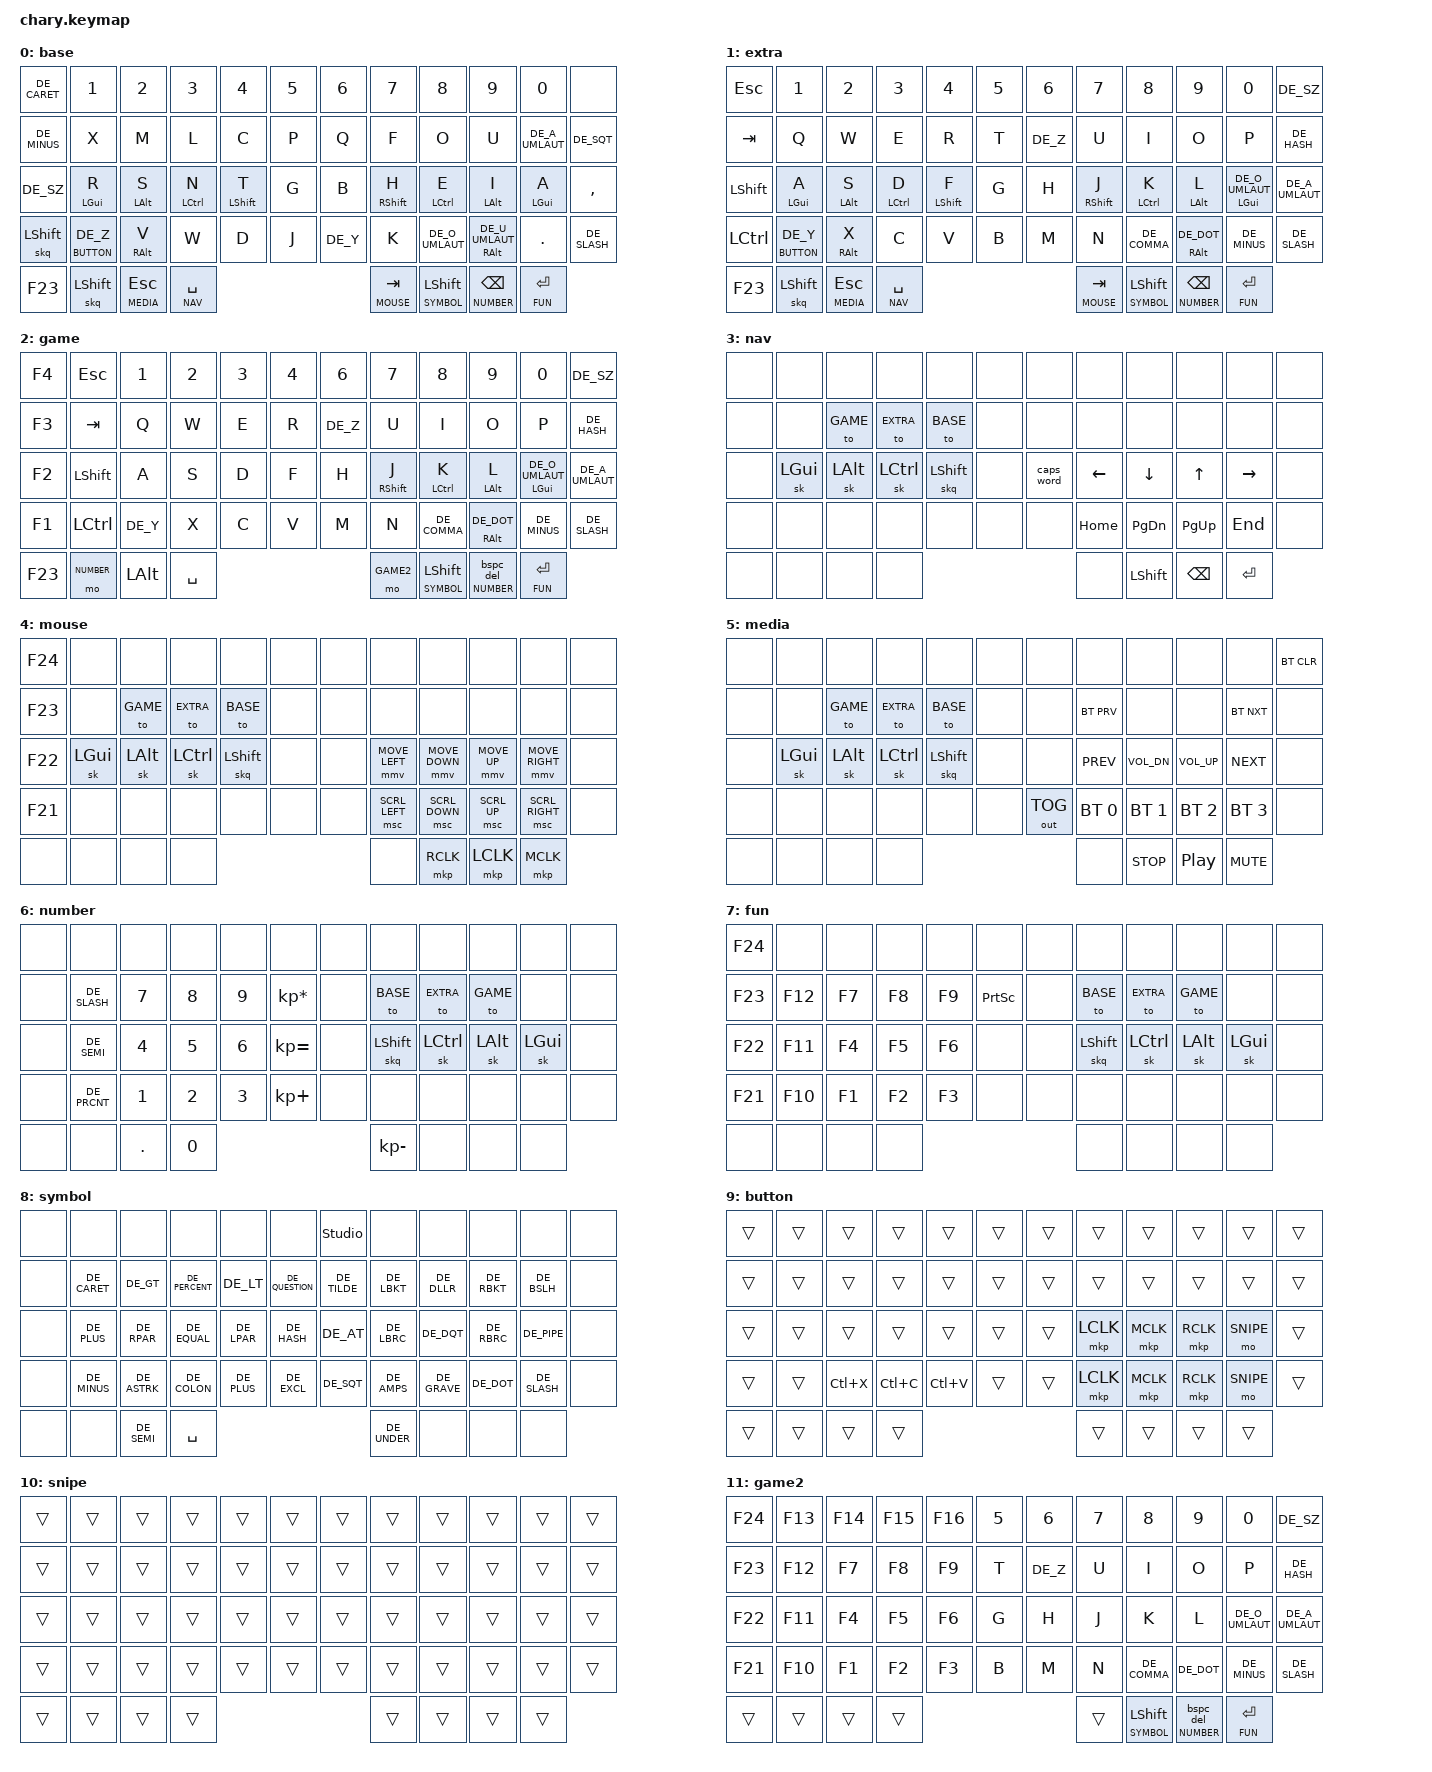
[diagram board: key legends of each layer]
#define ZMK_POINTING_DEFAULT_MOVE_VAL 1500  // default: 600
#include <behaviors.dtsi>
#include <dt-bindings/zmk/bt.h>
#include <dt-bindings/zmk/keys.h>
#include <dt-bindings/zmk/outputs.h>
#include <dt-bindings/zmk/mouse.h>
#include <locale/keys_de.h>

#define BASE    0
#define EXTRA   1
#define GAME    2
#define NAV     3
#define MOUSE   4
#define MEDIA   5
#define NUMBER  6
#define FUN     7
#define SYMBOL  8
#define BUTTON  9
#define SNIPE   10
#define GAME2   11

#define TAPPING_TERM 200
#define TAPPING_TERM_QUICK 150
#define REQUIRE_PRIOR_IDLE_MS 100

#define LEFT_THUMB 48 49 50 51 52
#define RIGHT_THUMB 53 54 55
#define LEFT_POS 0 1 2 3 4 5 12 13 14 15 16 17 24 25 26 27 28 29 36 37 38 39 40 41
#define RIGHT_POS 6 7 8 9 10 11 18 19 20 21 22 23 30 31 32 33 34 35 42 43 44 45 46 47

#include <dt-bindings/zmk/pointing.h>

&caps_word {
    continue-list = <SLASH LSHFT RSHFT>;
};

/ {
    behaviors {
        hrml: hrml {
            compatible = "zmk,behavior-hold-tap";
            #binding-cells = <2>;
            bindings = <&kp>, <&kp>;
            tapping-term-ms = <TAPPING_TERM>;
            quick-tap-ms = <175>;
            flavor = "balanced";
            hold-trigger-on-release;
            require-prior-idle-ms = <REQUIRE_PRIOR_IDLE_MS>;
            hold-trigger-key-positions = <RIGHT_POS LEFT_THUMB RIGHT_THUMB>;
        };

        hrmr: hrmr {
            compatible = "zmk,behavior-hold-tap";
            #binding-cells = <2>;
            bindings = <&kp>, <&kp>;
            tapping-term-ms = <TAPPING_TERM>;
            quick-tap-ms = <175>;
            flavor = "balanced";
            require-prior-idle-ms = <REQUIRE_PRIOR_IDLE_MS>;
            hold-trigger-key-positions = <LEFT_POS LEFT_THUMB RIGHT_THUMB>;
            hold-trigger-on-release;
        };

        hrml_s: hrml_s {
            compatible = "zmk,behavior-hold-tap";
            #binding-cells = <2>;
            bindings = <&kp>, <&kp>;
            tapping-term-ms = <TAPPING_TERM>;
            quick-tap-ms = <175>;
            flavor = "balanced";
            hold-trigger-key-positions = <RIGHT_POS LEFT_THUMB RIGHT_THUMB>;
            hold-trigger-on-release;
        };

        hrmr_s: hrmr_s {
            compatible = "zmk,behavior-hold-tap";
            #binding-cells = <2>;
            bindings = <&kp>, <&kp>;
            tapping-term-ms = <TAPPING_TERM>;
            quick-tap-ms = <175>;
            flavor = "balanced";
            hold-trigger-key-positions = <LEFT_POS LEFT_THUMB RIGHT_THUMB>;
            hold-trigger-on-release;
        };

        skq: sticky_key_quick_release {
            compatible = "zmk,behavior-sticky-key";
            #binding-cells = <1>;
            bindings = <&kp>;
            release-after-ms = <1000>;
            quick-release;
            ignore-modifiers;
        };

        bspc_del: backspace_del {
            compatible = "zmk,behavior-mod-morph";
            #binding-cells = <0>;
            bindings = <&kp BSPC>, <&kp DEL>;
            mods = <(MOD_LSFT|MOD_RSFT)>;
        };

        skq_mo: skq_mo {
            compatible = "zmk,behavior-hold-tap";
            bindings = <&mo>, <&skq>;

            #binding-cells = <2>;
            tapping-term-ms = <TAPPING_TERM_QUICK>;
            flavor = "tap-preferred";
        };

        lt_bspc: lt_bspc {
            compatible = "zmk,behavior-hold-tap";
            bindings = <&mo>, <&bspc_del>;

            #binding-cells = <2>;
            tapping-term-ms = <TAPPING_TERM_QUICK>;
            flavor = "tap-preferred";
        };
    };

    macros {
    };

    #include "combos.dtsi"

    keymap {
        compatible = "zmk,keymap";

        default_layer {
            display-name = "base";
            bindings = <
                &kp DE_CARET    &kp N1           &kp N2          &kp N3          &kp N4            &kp N5      &kp N6    &kp N7            &kp N8           &kp N9                  &kp N0           &none
                &kp DE_MINUS    &kp X            &kp M           &kp L           &kp C             &kp P       &kp Q     &kp F             &kp O            &kp U                   &kp DE_A_UMLAUT  &kp DE_SQT
                &kp DE_SZ       &hrml LGUI R     &hrml LALT S    &hrml LCTRL N   &hrml_s LSHIFT T  &kp G       &kp B     &hrmr_s RSHIFT H  &hrmr LCTRL E    &hrmr LALT I            &hrmr LGUI A     &kp COMMA
                &skq LSHFT      &lt BUTTON DE_Z  &hrml RALT V    &kp W           &kp D             &kp J       &kp DE_Y  &kp K             &kp DE_O_UMLAUT  &hrmr RALT DE_U_UMLAUT  &kp DOT          &kp DE_SLASH
                    &kp F23     &skq LSHIFT  &lt MEDIA ESC  &lt NAV SPACE  &lt MOUSE TAB                                      &skq_mo SYMBOL LSHFT  &lt NUMBER BSPC  &lt FUN ENTER
            >;
        };

        extra_layer {
            display-name = "extra";
            bindings = <
                &kp ESC   &kp N1            &kp N2        &kp N3         &kp N4             &kp N5    &kp N6   &kp N7            &kp N8          &kp N9             &kp N0                 &kp DE_SZ
                &kp TAB   &kp Q             &kp W         &kp E          &kp R              &kp T     &kp DE_Z &kp U             &kp I           &kp O              &kp P                  &kp DE_HASH
                &kp LSHFT &hrml LGUI A      &hrml LALT S  &hrml LCTRL D  &hrml_s LSHIFT F   &kp G     &kp H    &hrmr_s RSHIFT J  &hrmr LCTRL K   &hrmr LALT L       &hrmr LGUI DE_O_UMLAUT &kp DE_A_UMLAUT
                &kp LCTRL &lt BUTTON DE_Y   &hrml RALT X  &kp C          &kp V              &kp B     &kp M    &kp N             &kp DE_COMMA    &hrmr RALT DE_DOT  &kp DE_MINUS           &kp DE_SLASH
                    &kp F23      &skq LSHIFT  &lt MEDIA ESC  &lt NAV SPACE  &lt MOUSE TAB                                      &skq_mo SYMBOL LSHFT  &lt NUMBER BSPC  &lt FUN ENTER
            >;
        };

        game_layer {
            display-name = "game";
            bindings = <
                &kp F4   &kp ESC   &kp N1    &kp N2   &kp N3  &kp N4     &kp N6    &kp N7            &kp N8         &kp N9             &kp N0                   &kp DE_SZ
                &kp F3   &kp TAB   &kp Q     &kp W    &kp E   &kp R      &kp DE_Z  &kp U             &kp I          &kp O              &kp P                    &kp DE_HASH
                &kp F2   &kp LSHFT &kp A     &kp S    &kp D   &kp F      &kp H     &hrmr_s RSHIFT J  &hrmr LCTRL K  &hrmr LALT L       &hrmr LGUI DE_O_UMLAUT   &kp DE_A_UMLAUT
                &kp F1   &kp LCTRL &kp DE_Y  &kp X    &kp C   &kp V      &kp M     &kp N             &kp DE_COMMA   &hrmr RALT DE_DOT  &kp DE_MINUS             &kp DE_SLASH
                &kp F23  &mo NUMBER &kp LEFT_ALT &kp SPACE &mo GAME2               &skq_mo SYMBOL LSHFT  &lt_bspc NUMBER 0  &lt FUN ENTER
            >;
        };

        nav_layer {
            display-name = "nav";
            bindings = <
                &none    &none      &none      &none       &none        &none       &none       &none       &none       &none       &none       &none
                &none    &none      &to GAME   &to EXTRA   &to BASE     &none       &none       &none       &none       &none       &none       &none
                &none    &sk LGUI   &sk LALT   &sk LCTRL   &skq LSHFT   &none       &caps_word  &kp LEFT    &kp DOWN    &kp UP      &kp RIGHT   &none
                &none    &none      &none      &none       &none        &none       &none       &kp HOME    &kp PG_DN   &kp PG_UP   &kp END     &none
                &none    &none      &none      &none     &none                      &kp LSHFT   &kp BACKSPACE   &kp ENTER
            >;
        };

        mouse_layer {
            display-name = "mouse";
            bindings = <
                &kp F24  &none      &none      &none       &none        &none       &none   &none           &none           &none         &none             &none
                &kp F23    &none      &to GAME   &to EXTRA   &to BASE     &none       &none   &none           &none           &none         &none             &none
                &kp F22    &sk LGUI   &sk LALT   &sk LCTRL   &skq LSHFT   &none       &none   &mmv MOVE_LEFT  &mmv MOVE_DOWN  &mmv MOVE_UP  &mmv MOVE_RIGHT   &none
                &kp F21    &none      &none      &none       &none        &none       &none   &msc SCRL_LEFT  &msc SCRL_DOWN  &msc SCRL_UP  &msc SCRL_RIGHT   &none
                &none    &none      &none      &none     &none                      &mkp RCLK    &mkp LCLK   &mkp MCLK
            >;
        };

        media_layer {
            display-name = "media";
            bindings = <
                &none    &none      &none      &none       &none        &none       &none         &none         &none          &none         &none         &bt BT_CLR
                &none    &none      &to GAME   &to EXTRA  &to BASE     &none       &none         &bt BT_PRV    &none          &none         &bt BT_NXT    &none
                &none    &sk LGUI   &sk LALT   &sk LCTRL   &skq LSHFT   &none       &none         &kp C_PREV    &kp C_VOL_DN   &kp C_VOL_UP  &kp C_NEXT    &none
                &none    &none      &none      &none       &none        &none       &out OUT_TOG  &bt BT_SEL 0  &bt BT_SEL 1   &bt BT_SEL 2  &bt BT_SEL 3  &none
                &none    &none      &none      &none     &none                      &kp C_STOP    &kp C_PLAY_PAUSE   &kp C_MUTE
            >;
        };

        number_layer {
            display-name = "number";
            bindings = <
                &none    &none         &none      &none       &none        &none             &none   &none       &none       &none       &none       &none
                &none    &kp DE_SLASH  &kp N7     &kp N8      &kp N9       &kp KP_MULTIPLY   &none   &to BASE    &to EXTRA   &to GAME    &none       &none
                &none    &kp DE_SEMI   &kp N4     &kp N5      &kp N6       &kp KP_EQUAL      &none   &skq LSHFT  &sk LCTRL   &sk LALT    &sk LGUI    &none
                &none    &kp DE_PRCNT  &kp N1     &kp N2      &kp N3       &kp KP_PLUS       &none   &none       &none       &none       &none       &none
                &none    &none         &kp DOT    &kp N0      &kp KP_MINUS                      &none    &none   &none
            >;
        };

        fun_layer {
            display-name = "fun";
            bindings = <
                &kp F24  &none      &none      &none       &none    &none       &none   &none       &none       &none       &none       &none
                &kp F23  &kp F12    &kp F7     &kp F8      &kp F9   &kp PSCRN   &none   &to BASE    &to EXTRA   &to GAME    &none       &none
                &kp F22  &kp F11    &kp F4     &kp F5      &kp F6   &none       &none   &skq LSHFT  &sk LCTRL   &sk LALT    &sk LGUI    &none
                &kp F21  &kp F10    &kp F1     &kp F2      &kp F3   &none       &none   &none       &none       &none       &none       &none
                &none    &none      &none      &none     &none                      &none    &none   &none
            >;
        };

        symbol_layer {
            display-name = "symbol";
            bindings = <
                &none    &none          &none           &none             &none        &none            &studio_unlock &none        &none         &none        &none         &none
                &none    &kp DE_CARET   &kp DE_GT       &kp DE_PERCENT    &kp DE_LT    &kp DE_QUESTION  &kp DE_TILDE  &kp DE_LBKT  &kp DE_DLLR   &kp DE_RBKT  &kp DE_BSLH   &none
                &none    &kp DE_PLUS    &kp DE_RPAR     &kp DE_EQUAL      &kp DE_LPAR  &kp DE_HASH      &kp DE_AT     &kp DE_LBRC  &kp DE_DQT    &kp DE_RBRC  &kp DE_PIPE   &none
                &none    &kp DE_MINUS   &kp DE_ASTRK    &kp DE_COLON      &kp DE_PLUS  &kp DE_EXCL      &kp DE_SQT    &kp DE_AMPS  &kp DE_GRAVE  &kp DE_DOT   &kp DE_SLASH  &none
                &none    &none      &kp DE_SEMI      &kp SPACE     &kp DE_UNDER                         &none    &none   &none
            >;
        };

        button_layer {
            display-name = "button";
            bindings = <
                &trans  &trans  &trans      &trans      &trans      &trans   &trans  &trans      &trans      &trans      &trans     &trans
                &trans  &trans  &trans      &trans      &trans      &trans   &trans  &trans      &trans      &trans      &trans     &trans
                &trans  &trans  &trans      &trans      &trans      &trans   &trans  &mkp LCLK   &mkp MCLK   &mkp RCLK   &mo SNIPE  &trans
                &trans  &trans  &kp LC(X)   &kp LC(C)   &kp LC(V)   &trans   &trans  &mkp LCLK   &mkp MCLK   &mkp RCLK   &mo SNIPE  &trans
                &trans  &trans  &trans  &trans  &trans                      &trans  &trans  &trans
            >;
        };

        snipe_layer {
            display-name = "snipe";
            bindings = <
                &trans  &trans  &trans      &trans      &trans      &trans   &trans  &trans      &trans      &trans      &trans  &trans
                &trans  &trans  &trans      &trans      &trans      &trans   &trans  &trans      &trans      &trans      &trans  &trans
                &trans  &trans  &trans      &trans      &trans      &trans   &trans  &trans      &trans      &trans      &trans  &trans
                &trans  &trans  &trans      &trans      &trans      &trans   &trans  &trans      &trans      &trans      &trans  &trans
                &trans  &trans  &trans  &trans  &trans                      &trans  &trans  &trans
            >;
        };

        game2_layer {
            display-name = "game2";
            bindings = <
                &kp F24  &kp F13  &kp F14   &kp F15  &kp F16 &kp N5     &kp N6    &kp N7     &kp N8       &kp N9     &kp N0          &kp DE_SZ
                &kp F23  &kp F12  &kp F7    &kp F8   &kp F9  &kp T      &kp DE_Z  &kp U      &kp I        &kp O      &kp P           &kp DE_HASH
                &kp F22  &kp F11  &kp F4    &kp F5   &kp F6  &kp G      &kp H     &kp J      &kp K        &kp L      &kp DE_O_UMLAUT &kp DE_A_UMLAUT
                &kp F21  &kp F10  &kp F1    &kp F2   &kp F3  &kp B      &kp M     &kp N      &kp DE_COMMA &kp DE_DOT &kp DE_MINUS    &kp DE_SLASH
                &trans  &trans  &trans  &trans  &trans                      &skq_mo SYMBOL LSHFT  &lt_bspc NUMBER 0  &lt FUN ENTER
            >;
        };
    };
};
